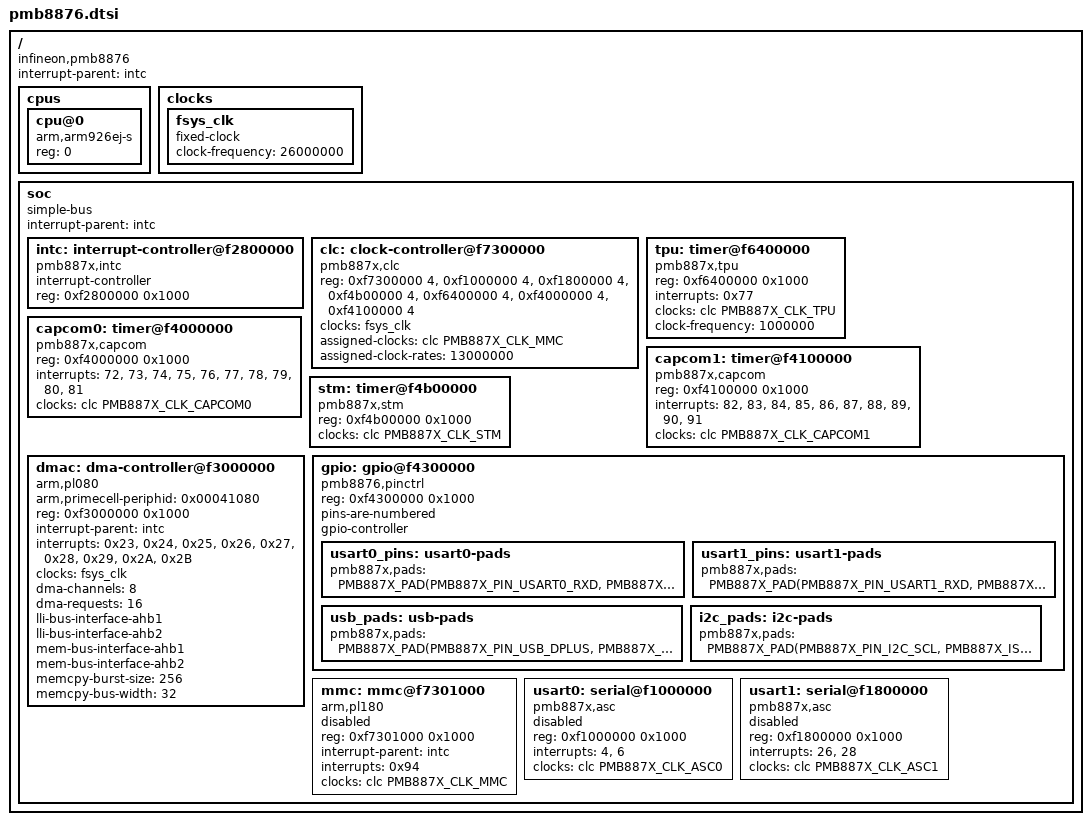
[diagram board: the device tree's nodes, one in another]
// SPDX-License-Identifier: GPL-2.0

#include <dt-bindings/clock/pmb887x.h>
#include <dt-bindings/pinctrl/pmb887x.h>

/ {
	#address-cells = <1>;
	#size-cells = <1>;
	compatible = "infineon,pmb8876";
	interrupt-parent = <&intc>;

	cpus {
		#address-cells = <1>;
		#size-cells = <0>;

		cpu@0 {
			compatible = "arm,arm926ej-s";
			device_type = "cpu";
			reg = <0>;
		};
	};
	
	clocks {
		fsys_clk: fsys_clk {
			compatible = "fixed-clock";
			#clock-cells = <0>;
			clock-frequency = <26000000>;
		};
	};
	
	soc {
		#address-cells = <1>;
		#size-cells = <1>;
		compatible = "simple-bus";
		interrupt-parent = <&intc>;
		ranges;
		
		intc: interrupt-controller@f2800000 {
			compatible = "pmb887x,intc";
			#interrupt-cells = <1>;
			interrupt-controller;
			reg = <0xf2800000 0x1000>;
		};
		
		clc: clock-controller@f7300000 {
			compatible = "pmb887x,clc";
			reg = <0xf7300000 4>,	/* PMB887X_CLK_MMC */
			      <0xf1000000 4>,	/* PMB887X_CLK_ASC0 */
			      <0xf1800000 4>,	/* PMB887X_CLK_ASC1 */
			      <0xf4b00000 4>,	/* PMB887X_CLK_STM */
			      <0xf6400000 4>,	/* PMB887X_CLK_TPU */
			      <0xf4000000 4>,	/* PMB887X_CLK_CAPCOM0 */
			      <0xf4100000 4>;	/* PMB887X_CLK_CAPCOM1 */
			clocks = <&fsys_clk>;
			#clock-cells = <1>;

			assigned-clocks = <&clc PMB887X_CLK_MMC>;
			assigned-clock-rates = <13000000>;
		};

		tpu: timer@f6400000 {
			compatible = "pmb887x,tpu";
			reg = <0xf6400000 0x1000>;
			interrupts = <0x77>;
			clocks = <&clc PMB887X_CLK_TPU>;
			clock-frequency = <1000000>;
		};

		capcom0: timer@f4000000 {
			compatible = "pmb887x,capcom";
			#address-cells = <1>;
			#size-cells = <1>;
			reg = <0xf4000000 0x1000>;
			ranges;
			interrupt-names = "t0", "t1", "cc0", "cc1", "cc2",
					  "cc3", "cc4", "cc5", "cc6", "cc7";
			interrupts = <72>, <73>, <74>, <75>, <76>,
				     <77>, <78>, <79>, <80>, <81>;
			clocks = <&clc PMB887X_CLK_CAPCOM0>;
		};

		capcom1: timer@f4100000 {
			compatible = "pmb887x,capcom";
			#address-cells = <1>;
			#size-cells = <1>;
			reg = <0xf4100000 0x1000>;
			ranges;
			interrupt-names = "t0", "t1", "cc0", "cc1", "cc2",
					  "cc3", "cc4", "cc5", "cc6", "cc7";
			interrupts = <82>, <83>, <84>, <85>, <86>,
				     <87>, <88>, <89>, <90>, <91>;
			clocks = <&clc PMB887X_CLK_CAPCOM1>;
		};

		stm: timer@f4b00000 {
			compatible = "pmb887x,stm";
			reg = <0xf4b00000 0x1000>;
			clocks = <&clc PMB887X_CLK_STM>;
		};
		
		dmac: dma-controller@f3000000 {
			compatible = "arm,pl080", "arm,primecell";
			arm,primecell-periphid = <0x00041080>;
			reg = <0xf3000000 0x1000>;
			interrupt-parent = <&intc>;
			interrupts = <0x23>, <0x24>, <0x25>, <0x26>, <0x27>, <0x28>, <0x29>, <0x2A>, <0x2B>;
			clocks = <&fsys_clk>;
			clock-names = "apb_pclk";
			#dma-cells = <2>;
			dma-channels = <8>;
			dma-requests = <16>;
			lli-bus-interface-ahb1;
			lli-bus-interface-ahb2;
			mem-bus-interface-ahb1;
			mem-bus-interface-ahb2;
			memcpy-burst-size = <256>;
			memcpy-bus-width = <32>;
		};
		
		gpio: gpio@f4300000 {
			compatible = "pmb8876,pinctrl";
			#address-cells = <1>;
			#size-cells = <1>;
			reg = <0xf4300000 0x1000>;
			pins-are-numbered;
			gpio-controller;
			#gpio-cells = <2>;
			#pinctrl-cells = <1>;

			/* Pad config shared by all pmb8876 boards: UART, USB, I2C */
			usart0_pins: usart0-pads {
				pmb887x,pads = <
					PMB887X_PAD(PMB887X_PIN_USART0_RXD, PMB887X_IS_ALT0 | PMB887X_PPEN_OPENDRAIN | PMB887X_PDPU_PULLUP)
					PMB887X_PAD(PMB887X_PIN_USART0_TXD, PMB887X_OS_ALT0 | PMB887X_PDPU_PULLUP)
				>;
			};

			usart1_pins: usart1-pads {
				pmb887x,pads = <
					PMB887X_PAD(PMB887X_PIN_USART1_RXD, PMB887X_IS_ALT0 | PMB887X_PPEN_OPENDRAIN | PMB887X_PDPU_PULLUP)
					PMB887X_PAD(PMB887X_PIN_USART1_TXD, PMB887X_OS_ALT0)
				>;
			};

			usb_pads: usb-pads {
				pmb887x,pads = <
					PMB887X_PAD(PMB887X_PIN_USB_DPLUS, PMB887X_PS_MANUAL | PMB887X_DIR_OUT)
					PMB887X_PAD(PMB887X_PIN_USB_DMINUS, PMB887X_OS_ALT3)
				>;
			};

			i2c_pads: i2c-pads {
				pmb887x,pads = <
					PMB887X_PAD(PMB887X_PIN_I2C_SCL, PMB887X_IS_ALT0 | PMB887X_OS_ALT0 | PMB887X_PPEN_OPENDRAIN)
					PMB887X_PAD(PMB887X_PIN_I2C_SDA, PMB887X_IS_ALT0 | PMB887X_OS_ALT0 | PMB887X_PPEN_OPENDRAIN)
				>;
			};
		};
		
		mmc: mmc@f7301000 {
			compatible = "arm,pl180", "arm,primecell";
			reg = <0xf7301000 0x1000>;
			dma-names = "mmci0_rx", "mmci0_tx";
			interrupt-parent = <&intc>;
			interrupts = <0x94>;
			clocks = <&clc PMB887X_CLK_MMC>;
			clock-names = "apb_pclk";
			status = "disabled";
		};
		
		usart0: serial@f1000000 {
			compatible = "pmb887x,asc";
			reg = <0xf1000000 0x1000>;
			interrupt-names = "tx", "rx";
			interrupts = <4>, <6>;
			clocks = <&clc PMB887X_CLK_ASC0>;
			status = "disabled";
		};
		
		usart1: serial@f1800000 {
			compatible = "pmb887x,asc";
			reg = <0xf1800000 0x1000>;
			interrupt-names = "tx", "rx";
			interrupts = <26>, <28>;
			clocks = <&clc PMB887X_CLK_ASC1>;
			status = "disabled";
		};
	};
};
